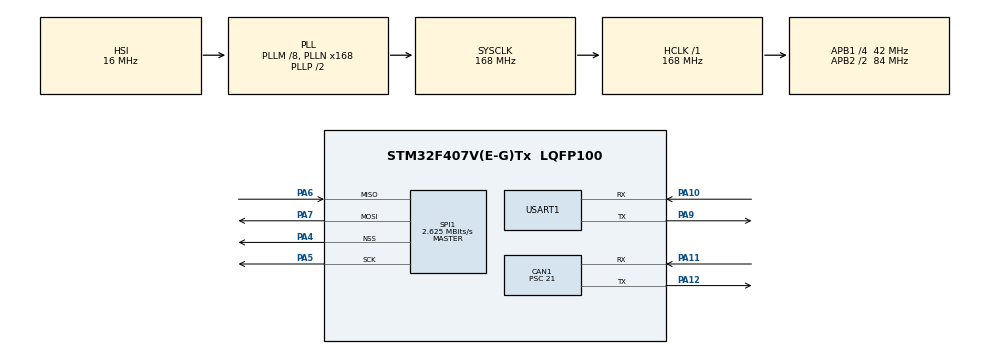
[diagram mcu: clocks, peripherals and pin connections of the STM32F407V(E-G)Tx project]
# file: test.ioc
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CAN1.ABOM=ENABLE
CAN1.AWUM=ENABLE
CAN1.BS2=CAN_BS2_2TQ
CAN1.CalculateBaudRate=500000
CAN1.CalculateTimeBit=2000
CAN1.CalculateTimeQuantum=500.0
CAN1.Prescaler=21
Mcu.Family=STM32F4
Mcu.Name=STM32F407V(E-G)Tx
Mcu.Package=LQFP100
NVIC.CAN1_RX0_IRQn=true\:2\:0\:true\:false\:true\:true\:true\:true
NVIC.PriorityGroup=NVIC_PRIORITYGROUP_4
NVIC.SPI1_IRQn=true\:3\:0\:true\:false\:true\:true\:true\:true
PA10.Mode=Asynchronous
PA10.Signal=USART1_RX
PA11.Mode=CAN_Activate
PA11.Signal=CAN1_RX
PA12.Mode=CAN_Activate
PA12.Signal=CAN1_TX
PA13.Mode=Serial_Wire
PA13.Signal=SYS_JTMS-SWDIO
PA14.Mode=Serial_Wire
PA14.Signal=SYS_JTCK-SWCLK
PA4.Mode=NSS_Signal_Hard_Output
PA4.Signal=SPI1_NSS
PA5.Mode=Full_Duplex_Master
PA5.Signal=SPI1_SCK
PA6.Mode=Full_Duplex_Master
PA6.Signal=SPI1_MISO
PA7.Mode=Full_Duplex_Master
PA7.Signal=SPI1_MOSI
PA9.Mode=Asynchronous
PA9.Signal=USART1_TX
PC14-OSC32_IN.Mode=LSE-External-Oscillator
PC14-OSC32_IN.Signal=RCC_OSC32_IN
PC15-OSC32_OUT.Mode=LSE-External-Oscillator
PC15-OSC32_OUT.Signal=RCC_OSC32_OUT
PH0-OSC_IN.Mode=HSE-External-Oscillator
PH0-OSC_IN.Signal=RCC_OSC_IN
PH1-OSC_OUT.Mode=HSE-External-Oscillator
PH1-OSC_OUT.Signal=RCC_OSC_OUT
ProjectManager.HeapSize=0x200
ProjectManager.StackSize=0x400
ProjectManager.TargetToolchain=MDK-ARM V5.32
RCC.48MHZClocksFreq_Value=84000000
RCC.AHBFreq_Value=168000000
RCC.APB1CLKDivider=RCC_HCLK_DIV4
RCC.APB1Freq_Value=42000000
RCC.APB1TimFreq_Value=84000000
RCC.APB2CLKDivider=RCC_HCLK_DIV2
RCC.APB2Freq_Value=84000000
RCC.APB2TimFreq_Value=168000000
RCC.CortexFreq_Value=168000000
RCC.HCLKFreq_Value=168000000
RCC.HSE_VALUE=25000000
RCC.HSI_VALUE=16000000
RCC.PLLM=8
RCC.PLLN=168
RCC.SYSCLKFreq_VALUE=168000000
RCC.SYSCLKSource=RCC_SYSCLKSOURCE_PLLCLK
RCC.VCOOutputFreq_Value=336000000
SPI1.BaudRatePrescaler=SPI_BAUDRATEPRESCALER_32
SPI1.CalculateBaudRate=2.625 MBits/s
SPI1.Direction=SPI_DIRECTION_2LINES
SPI1.Mode=SPI_MODE_MASTER
SPI1.VirtualNSS=VM_NSSHARD
SPI1.VirtualType=VM_MASTER
USART1.VirtualMode=VM_ASYNC
board=custom

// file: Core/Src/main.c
/* USER CODE BEGIN Header */
/**
  ******************************************************************************
  * @file           : main.c
  * @brief          : Main program body
  ******************************************************************************
  * @attention
  *
  * Copyright (c) 2023 STMicroelectronics.
  * All rights reserved.
  *
  * This software is licensed under terms that can be found in the LICENSE file
  * in the root directory of this software component.
  * If no LICENSE file comes with this software, it is provided AS-IS.
  *
  ******************************************************************************
  */
/* USER CODE END Header */
#include "main.h"
#include "can.h"
#include "spi.h"
#include "usart.h"
#include "gpio.h"

/* USER CODE BEGIN PV */
uint8_t receive[1];
uint8_t receBuff[4096];
uint8_t RX_STA = 0;
uint8_t  spi_data[9]={0x61,0x6e,0x64,0x79,0x7a,0x7a,0x7a,0x7a,0x61};
/* USER CODE END PV */

void SystemClock_Config(void);

/* USER CODE BEGIN 0 */
void HAL_SPI_RxCpltCallback(SPI_HandleTypeDef *hspi)
{
   if(hspi->Instance==SPI1)
  {
    receBuff[RX_STA] = receive[0];
    RX_STA++;
//    HAL_SPI_Receive_IT(&hspi1, receive, 1);
  }
  printf("success into receive it\n");
}
/* USER CODE END 0 */

int main(void)
{

  /* MCU Configuration--------------------------------------------------------*/

  /* Reset of all peripherals, Initializes the Flash interface and the Systick. */
  HAL_Init();

  /* Configure the system clock */
  SystemClock_Config();

  /* USER CODE BEGIN SysInit */

    SysTick_Init();
  /* USER CODE END SysInit */

  /* Initialize all configured peripherals */
  MX_GPIO_Init();
  MX_USART1_UART_Init();
  MX_CAN1_Init();
  MX_SPI1_Init();
  /* USER CODE BEGIN 2 */
    CAN_Init();
    HAL_CAN_Start(&hcan1);
//HAL_SPI_Receive_IT(&hspi1, receive, 1); //打开SPI接收中断
printf("----------------------------------------\r\n");
CANSendData_fixed_data();
  /* USER CODE END 2 */

  /* Infinite loop */
  while (1)
  {
    printf("ok\n");
      delay_ms(1000);
//        for(int i = 0; i <= RX_STA; i++)
//      printf("%x\n",receBuff[i]);
spi_send_data(spi_data,9);
  }
}

void SystemClock_Config(void)
{
  RCC_OscInitTypeDef RCC_OscInitStruct = {0};
  RCC_ClkInitTypeDef RCC_ClkInitStruct = {0};

  /** Configure the main internal regulator output voltage
  */
  __HAL_RCC_PWR_CLK_ENABLE();
  __HAL_PWR_VOLTAGESCALING_CONFIG(PWR_REGULATOR_VOLTAGE_SCALE1);

  /** Initializes the RCC Oscillators according to the specified parameters
  * in the RCC_OscInitTypeDef structure.
  */
  RCC_OscInitStruct.OscillatorType = RCC_OSCILLATORTYPE_HSI;
  RCC_OscInitStruct.HSIState = RCC_HSI_ON;
  RCC_OscInitStruct.HSICalibrationValue = RCC_HSICALIBRATION_DEFAULT;
  RCC_OscInitStruct.PLL.PLLState = RCC_PLL_ON;
  RCC_OscInitStruct.PLL.PLLSource = RCC_PLLSOURCE_HSI;
  RCC_OscInitStruct.PLL.PLLM = 8;
  RCC_OscInitStruct.PLL.PLLN = 168;
  RCC_OscInitStruct.PLL.PLLP = RCC_PLLP_DIV2;
  RCC_OscInitStruct.PLL.PLLQ = 4;
  if (HAL_RCC_OscConfig(&RCC_OscInitStruct) != HAL_OK)
  {
    Error_Handler();
  }

  /** Initializes the CPU, AHB and APB buses clocks
  */
  RCC_ClkInitStruct.ClockType = RCC_CLOCKTYPE_HCLK|RCC_CLOCKTYPE_SYSCLK
                              |RCC_CLOCKTYPE_PCLK1|RCC_CLOCKTYPE_PCLK2;
  RCC_ClkInitStruct.SYSCLKSource = RCC_SYSCLKSOURCE_PLLCLK;
  RCC_ClkInitStruct.AHBCLKDivider = RCC_SYSCLK_DIV1;
  RCC_ClkInitStruct.APB1CLKDivider = RCC_HCLK_DIV4;
  RCC_ClkInitStruct.APB2CLKDivider = RCC_HCLK_DIV2;

  if (HAL_RCC_ClockConfig(&RCC_ClkInitStruct, FLASH_LATENCY_5) != HAL_OK)
  {
    Error_Handler();
  }
}

void Error_Handler(void)
{
  __disable_irq();
  while (1)
  {
  }
}
